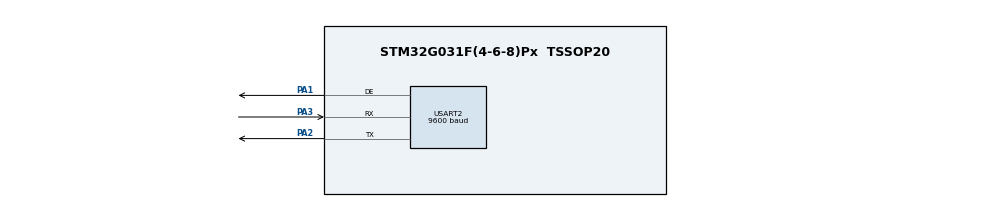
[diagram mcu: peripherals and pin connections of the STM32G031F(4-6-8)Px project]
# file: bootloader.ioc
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Mcu.Family=STM32G0
Mcu.Name=STM32G031F(4-6-8)Px
Mcu.Package=TSSOP20
NVIC.USART2_IRQn=true\:0\:0\:false\:false\:true\:true\:true\:true
PA1.Mode=Hardware Flow Control (RS485)
PA1.Signal=USART2_DE
PA14-BOOT0__PA15.StandardMode=true
PA2.Mode=Asynchronous
PA2.Signal=USART2_TX
PA3.Mode=Asynchronous
PA3.Signal=USART2_RX
PB0__PB1__PB2__PA8.StandardMode=true
PB3__PB4__PB5__PB6.StandardMode=true
PB7__PB8.StandardMode=true
PC14-OSC32_IN\ (PC14)__PB9.StandardMode=true
ProjectManager.HeapSize=0x200
ProjectManager.StackSize=0x400
ProjectManager.TargetToolchain=STM32CubeIDE
RCC.AHBFreq_Value=16000000
RCC.CortexFreq_Value=16000000
RCC.EXTERNAL_CLOCK_VALUE=12288000
RCC.HCLKFreq_Value=16000000
RCC.HSE_VALUE=8000000
RCC.HSI_VALUE=16000000
RCC.LSE_VALUE=32768
RCC.SYSCLKFreq_VALUE=16000000
RCC.VCOOutputFreq_Value=128000000
USART2.BaudRate=9600
USART2.VirtualMode-Asynchronous=VM_ASYNC
USART2.VirtualMode-Hardware\ Flow\ Control\ (RS485)=VM_ASYNC
board=custom

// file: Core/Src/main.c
/* USER CODE BEGIN Header */
/**
  ******************************************************************************
  * @file           : main.c
  * @brief          : Main program body
  ******************************************************************************
  * @attention
  *
  * Copyright (c) 2022 STMicroelectronics.
  * All rights reserved.
  *
  * This software is licensed under terms that can be found in the LICENSE file
  * in the root directory of this software component.
  * If no LICENSE file comes with this software, it is provided AS-IS.
  *
  ******************************************************************************
  */
/* USER CODE END Header */
#include "main.h"

/* USER CODE BEGIN Includes */
#include "app.h"
/* USER CODE END Includes */

void SystemClock_Config(void);
static void MX_GPIO_Init(void);
static void MX_USART2_UART_Init(void);

int main(void)
{

  /* MCU Configuration--------------------------------------------------------*/

  /* Reset of all peripherals, Initializes the Flash interface and the Systick. */
  LL_APB2_GRP1_EnableClock(LL_APB2_GRP1_PERIPH_SYSCFG);
  LL_APB1_GRP1_EnableClock(LL_APB1_GRP1_PERIPH_PWR);

  /* SysTick_IRQn interrupt configuration */
  NVIC_SetPriority(SysTick_IRQn, 3);

  /* Configure the system clock */
  SystemClock_Config();

  /* Initialize all configured peripherals */
  MX_GPIO_Init();
  MX_USART2_UART_Init();
  /* USER CODE BEGIN 2 */
  LL_USART_EnableIT_RXNE(USART2);
  LL_USART_EnableIT_TXE(USART2);
  app_init();
  /* USER CODE END 2 */

  /* Infinite loop */
  while (1)
  {

    /* USER CODE BEGIN 3 */
	  app_loop();
  }
  /* USER CODE END 3 */
}

void SystemClock_Config(void)
{
  /* HSI configuration and activation */
  LL_RCC_HSI_Enable();
  while(LL_RCC_HSI_IsReady() != 1)
  {
  }

  /* Set AHB prescaler*/
  LL_RCC_SetAHBPrescaler(LL_RCC_SYSCLK_DIV_1);

  /* Sysclk activation on the HSI */
  LL_RCC_SetSysClkSource(LL_RCC_SYS_CLKSOURCE_HSI);
  while(LL_RCC_GetSysClkSource() != LL_RCC_SYS_CLKSOURCE_STATUS_HSI)
  {
  }

  /* Set APB1 prescaler*/
  LL_RCC_SetAPB1Prescaler(LL_RCC_APB1_DIV_1);

  LL_Init1msTick(16000000);

  /* Update CMSIS variable (which can be updated also through SystemCoreClockUpdate function) */
  LL_SetSystemCoreClock(16000000);
}

static void MX_USART2_UART_Init(void)
{

  LL_USART_InitTypeDef USART_InitStruct = {0};

  LL_GPIO_InitTypeDef GPIO_InitStruct = {0};

  /* Peripheral clock enable */
  LL_APB1_GRP1_EnableClock(LL_APB1_GRP1_PERIPH_USART2);

  LL_IOP_GRP1_EnableClock(LL_IOP_GRP1_PERIPH_GPIOA);
  /**USART2 GPIO Configuration
  PA1   ------> USART2_DE
  PA2   ------> USART2_TX
  PA3   ------> USART2_RX
  */
  GPIO_InitStruct.Pin = LL_GPIO_PIN_1;
  GPIO_InitStruct.Mode = LL_GPIO_MODE_ALTERNATE;
  GPIO_InitStruct.Speed = LL_GPIO_SPEED_FREQ_LOW;
  GPIO_InitStruct.OutputType = LL_GPIO_OUTPUT_PUSHPULL;
  GPIO_InitStruct.Pull = LL_GPIO_PULL_NO;
  GPIO_InitStruct.Alternate = LL_GPIO_AF_1;
  LL_GPIO_Init(GPIOA, &GPIO_InitStruct);

  GPIO_InitStruct.Pin = LL_GPIO_PIN_2;
  GPIO_InitStruct.Mode = LL_GPIO_MODE_ALTERNATE;
  GPIO_InitStruct.Speed = LL_GPIO_SPEED_FREQ_LOW;
  GPIO_InitStruct.OutputType = LL_GPIO_OUTPUT_PUSHPULL;
  GPIO_InitStruct.Pull = LL_GPIO_PULL_NO;
  GPIO_InitStruct.Alternate = LL_GPIO_AF_1;
  LL_GPIO_Init(GPIOA, &GPIO_InitStruct);

  GPIO_InitStruct.Pin = LL_GPIO_PIN_3;
  GPIO_InitStruct.Mode = LL_GPIO_MODE_ALTERNATE;
  GPIO_InitStruct.Speed = LL_GPIO_SPEED_FREQ_LOW;
  GPIO_InitStruct.OutputType = LL_GPIO_OUTPUT_PUSHPULL;
  GPIO_InitStruct.Pull = LL_GPIO_PULL_NO;
  GPIO_InitStruct.Alternate = LL_GPIO_AF_1;
  LL_GPIO_Init(GPIOA, &GPIO_InitStruct);

  /* USART2 interrupt Init */
  NVIC_SetPriority(USART2_IRQn, 0);
  NVIC_EnableIRQ(USART2_IRQn);

  USART_InitStruct.PrescalerValue = LL_USART_PRESCALER_DIV1;
  USART_InitStruct.BaudRate = 9600;
  USART_InitStruct.DataWidth = LL_USART_DATAWIDTH_8B;
  USART_InitStruct.StopBits = LL_USART_STOPBITS_1;
  USART_InitStruct.Parity = LL_USART_PARITY_NONE;
  USART_InitStruct.TransferDirection = LL_USART_DIRECTION_TX_RX;
  USART_InitStruct.HardwareFlowControl = LL_USART_HWCONTROL_NONE;
  USART_InitStruct.OverSampling = LL_USART_OVERSAMPLING_16;
  LL_USART_Init(USART2, &USART_InitStruct);
  LL_USART_EnableDEMode(USART2);
  LL_USART_SetDESignalPolarity(USART2, LL_USART_DE_POLARITY_HIGH);
  LL_USART_SetDEAssertionTime(USART2, 0);
  LL_USART_SetDEDeassertionTime(USART2, 0);
  LL_USART_ConfigAsyncMode(USART2);

  LL_USART_Enable(USART2);

  /* Polling USART2 initialisation */
  while((!(LL_USART_IsActiveFlag_TEACK(USART2))) || (!(LL_USART_IsActiveFlag_REACK(USART2))))
  {
  }

}

static void MX_GPIO_Init(void)
{

  /* GPIO Ports Clock Enable */
  LL_IOP_GRP1_EnableClock(LL_IOP_GRP1_PERIPH_GPIOA);

}

void Error_Handler(void)
{
  __disable_irq();
  while (1)
  {
  }
}
